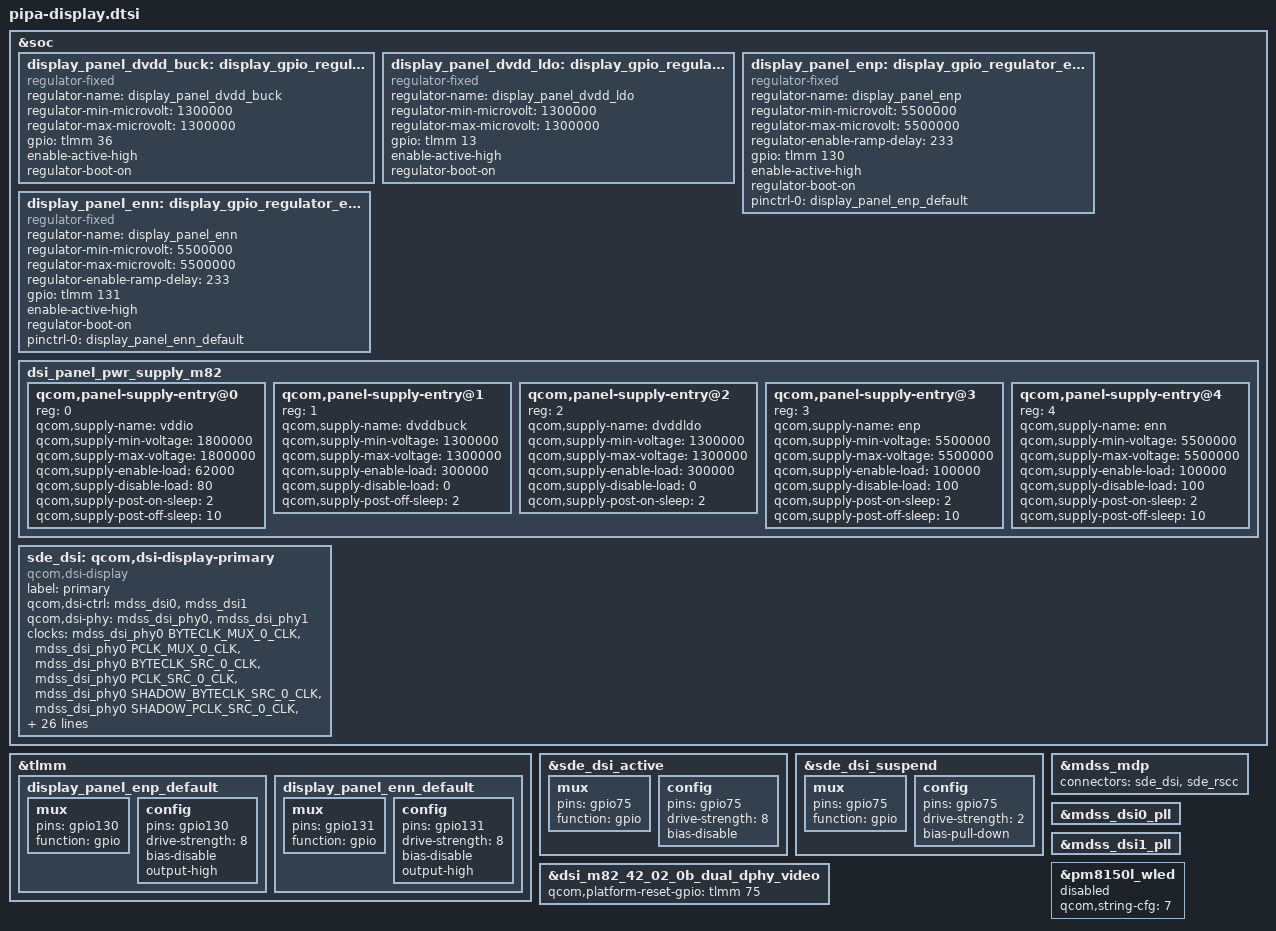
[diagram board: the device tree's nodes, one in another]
/* Boot display and panel power for the Xiaomi Pad 6 (pipa). */

#include <dt-bindings/clock/mdss-7nm-pll-clk.h>
#include "display/dsi-panel-pipa-m82-42-02-0b-video.dtsi"

&soc {
	display_panel_dvdd_buck: display_gpio_regulator_dvdd_buck {
		compatible = "regulator-fixed";
		regulator-name = "display_panel_dvdd_buck";
		regulator-min-microvolt = <1300000>;
		regulator-max-microvolt = <1300000>;
		gpio = <&tlmm 36 0>;
		enable-active-high;
		regulator-boot-on;
	};

	display_panel_dvdd_ldo: display_gpio_regulator_dvdd_ldo {
		compatible = "regulator-fixed";
		regulator-name = "display_panel_dvdd_ldo";
		regulator-min-microvolt = <1300000>;
		regulator-max-microvolt = <1300000>;
		gpio = <&tlmm 13 0>;
		enable-active-high;
		regulator-boot-on;
	};

	display_panel_enp: display_gpio_regulator_enp {
		compatible = "regulator-fixed";
		regulator-name = "display_panel_enp";
		regulator-min-microvolt = <5500000>;
		regulator-max-microvolt = <5500000>;
		regulator-enable-ramp-delay = <233>;
		gpio = <&tlmm 130 0>;
		enable-active-high;
		regulator-boot-on;
		pinctrl-names = "default";
		pinctrl-0 = <&display_panel_enp_default>;
	};

	display_panel_enn: display_gpio_regulator_enn {
		compatible = "regulator-fixed";
		regulator-name = "display_panel_enn";
		regulator-min-microvolt = <5500000>;
		regulator-max-microvolt = <5500000>;
		regulator-enable-ramp-delay = <233>;
		gpio = <&tlmm 131 0>;
		enable-active-high;
		regulator-boot-on;
		pinctrl-names = "default";
		pinctrl-0 = <&display_panel_enn_default>;
	};

	dsi_panel_pwr_supply_m82: dsi_panel_pwr_supply_m82 {
		#address-cells = <1>;
		#size-cells = <0>;

		qcom,panel-supply-entry@0 {
			reg = <0>;
			qcom,supply-name = "vddio";
			qcom,supply-min-voltage = <1800000>;
			qcom,supply-max-voltage = <1800000>;
			qcom,supply-enable-load = <62000>;
			qcom,supply-disable-load = <80>;
			qcom,supply-post-on-sleep = <2>;
			qcom,supply-post-off-sleep = <10>;
		};

		qcom,panel-supply-entry@1 {
			reg = <1>;
			qcom,supply-name = "dvddbuck";
			qcom,supply-min-voltage = <1300000>;
			qcom,supply-max-voltage = <1300000>;
			qcom,supply-enable-load = <300000>;
			qcom,supply-disable-load = <0>;
			qcom,supply-post-off-sleep = <2>;
		};

		qcom,panel-supply-entry@2 {
			reg = <2>;
			qcom,supply-name = "dvddldo";
			qcom,supply-min-voltage = <1300000>;
			qcom,supply-max-voltage = <1300000>;
			qcom,supply-enable-load = <300000>;
			qcom,supply-disable-load = <0>;
			qcom,supply-post-on-sleep = <2>;
		};

		qcom,panel-supply-entry@3 {
			reg = <3>;
			qcom,supply-name = "enp";
			qcom,supply-min-voltage = <5500000>;
			qcom,supply-max-voltage = <5500000>;
			qcom,supply-enable-load = <100000>;
			qcom,supply-disable-load = <100>;
			qcom,supply-post-on-sleep = <2>;
			qcom,supply-post-off-sleep = <10>;
		};

		qcom,panel-supply-entry@4 {
			reg = <4>;
			qcom,supply-name = "enn";
			qcom,supply-min-voltage = <5500000>;
			qcom,supply-max-voltage = <5500000>;
			qcom,supply-enable-load = <100000>;
			qcom,supply-disable-load = <100>;
			qcom,supply-post-on-sleep = <2>;
			qcom,supply-post-off-sleep = <10>;
		};
	};

	sde_dsi: qcom,dsi-display-primary {
		compatible = "qcom,dsi-display";
		label = "primary";
		qcom,dsi-ctrl = <&mdss_dsi0 &mdss_dsi1>;
		qcom,dsi-phy = <&mdss_dsi_phy0 &mdss_dsi_phy1>;

		clocks = <&mdss_dsi_phy0 BYTECLK_MUX_0_CLK>,
			 <&mdss_dsi_phy0 PCLK_MUX_0_CLK>,
			 <&mdss_dsi_phy0 BYTECLK_SRC_0_CLK>,
			 <&mdss_dsi_phy0 PCLK_SRC_0_CLK>,
			 <&mdss_dsi_phy0 SHADOW_BYTECLK_SRC_0_CLK>,
			 <&mdss_dsi_phy0 SHADOW_PCLK_SRC_0_CLK>,
			 <&mdss_dsi_phy1 BYTECLK_MUX_1_CLK>,
			 <&mdss_dsi_phy1 PCLK_MUX_1_CLK>,
			 <&mdss_dsi_phy1 BYTECLK_SRC_1_CLK>,
			 <&mdss_dsi_phy1 PCLK_SRC_1_CLK>,
			 <&mdss_dsi_phy1 SHADOW_BYTECLK_SRC_1_CLK>,
			 <&mdss_dsi_phy1 SHADOW_PCLK_SRC_1_CLK>;
		clock-names = "mux_byte_clk0", "mux_pixel_clk0",
			      "src_byte_clk0", "src_pixel_clk0",
			      "shadow_byte_clk0", "shadow_pixel_clk0",
			      "mux_byte_clk1", "mux_pixel_clk1",
			      "src_byte_clk1", "src_pixel_clk1",
			      "shadow_byte_clk1", "shadow_pixel_clk1";

		pinctrl-names = "panel_active", "panel_suspend";
		pinctrl-0 = <&sde_dsi_active &sde_te_active>;
		pinctrl-1 = <&sde_dsi_suspend &sde_te_suspend>;
		qcom,platform-te-gpio = <&tlmm 66 0>;
		qcom,panel-te-source = <0>;
		qcom,mdp = <&mdss_mdp>;
	};
};

&tlmm {
	display_panel_enp_default: display_panel_enp_default {
		mux {
			pins = "gpio130";
			function = "gpio";
		};
		config {
			pins = "gpio130";
			drive-strength = <8>;
			bias-disable;
			output-high;
		};
	};

	display_panel_enn_default: display_panel_enn_default {
		mux {
			pins = "gpio131";
			function = "gpio";
		};
		config {
			pins = "gpio131";
			drive-strength = <8>;
			bias-disable;
			output-high;
		};
	};
};

&sde_dsi_active {
	mux {
		pins = "gpio75";
		function = "gpio";
	};
	config {
		pins = "gpio75";
		drive-strength = <8>;
		bias-disable;
	};
};

&sde_dsi_suspend {
	mux {
		pins = "gpio75";
		function = "gpio";
	};
	config {
		pins = "gpio75";
		drive-strength = <2>;
		bias-pull-down;
	};
};

&sde_dsi {
	qcom,platform-te-gpio = <&tlmm 66 0>;
	qcom,panel-te-source = <0>;
	qcom,panel-supply-entries = <&dsi_panel_pwr_supply_m82>;
	qcom,mdss-dsi-bl-pmic-control-type = "bl_ctrl_wled";
	qcom,mdss-dsi-bl-min-level = <2>;
	qcom,mdss-dsi-bl-max-level = <4095>;
	qcom,mdss-brightness-max-level = <4095>;
	qcom,mdss-brightness-init-level = <307>;
	vddio-supply = <&pm8150_l14>;
	dvddbuck-supply = <&display_panel_dvdd_buck>;
	dvddldo-supply = <&display_panel_dvdd_ldo>;
	enp-supply = <&display_panel_enp>;
	enn-supply = <&display_panel_enn>;
	qcom,mdp = <&mdss_mdp>;
	qcom,dsi-default-panel = <&dsi_m82_42_02_0b_dual_dphy_video>;
};

&mdss_mdp {
	connectors = <&sde_dsi &sde_rscc>;
};

&mdss_dsi0_pll {
	/delete-property/ qcom,dsi-pll-ssc-en;
};

&mdss_dsi1_pll {
	/delete-property/ qcom,dsi-pll-ssc-en;
};

&dsi_m82_42_02_0b_dual_dphy_video {
	qcom,platform-reset-gpio = <&tlmm 75 0>;
};

&pm8150l_wled {
	status = "disabled";
	qcom,string-cfg = <7>;
};
